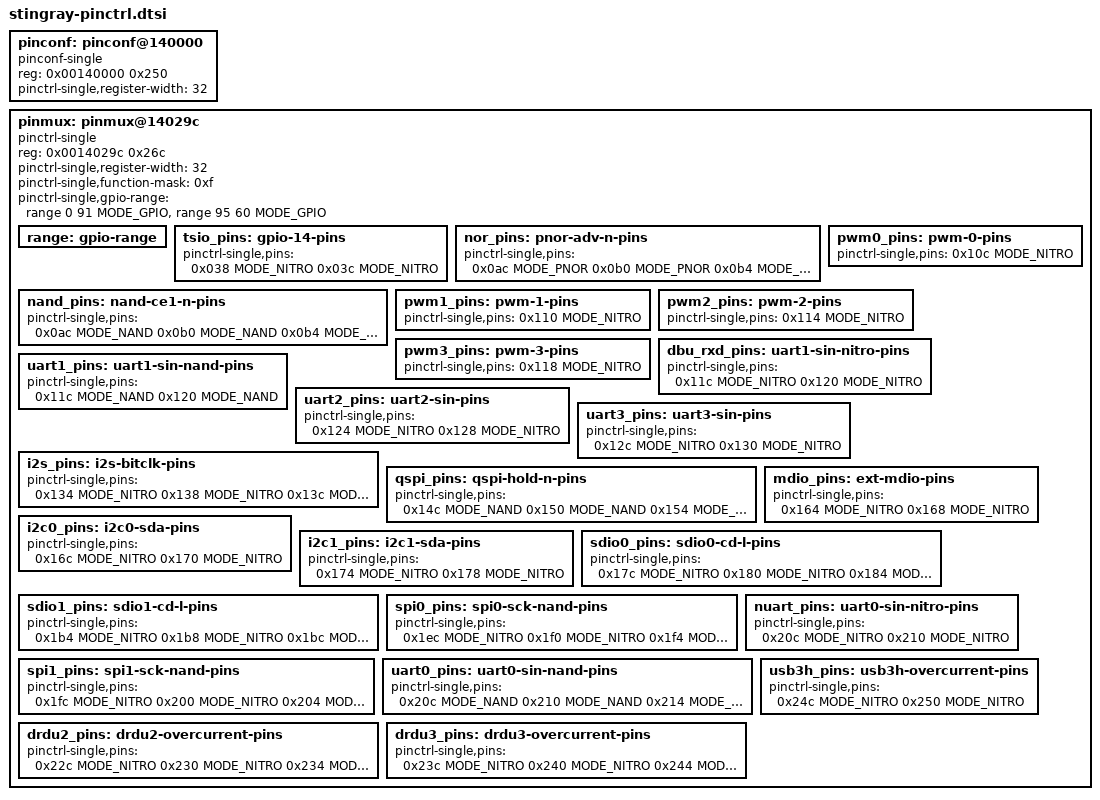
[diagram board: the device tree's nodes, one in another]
#include <dt-bindings/pinctrl/brcm,pinctrl-stingray.h>
		pinconf: pinconf@140000 {
			compatible = "pinconf-single";
			reg = <0x00140000 0x250>;
			pinctrl-single,register-width = <32>;
		};
		pinmux: pinmux@14029c {
			compatible = "pinctrl-single";
			reg = <0x0014029c 0x26c>;
			#address-cells = <1>;
			#size-cells = <0>;
			pinctrl-single,register-width = <32>;
			pinctrl-single,function-mask = <0xf>;
			pinctrl-single,gpio-range = <
				&range 0  91 MODE_GPIO
				&range 95 60 MODE_GPIO
				>;
			range: gpio-range {
				#pinctrl-single,gpio-range-cells = <3>;
			};
			tsio_pins: gpio-14-pins {
				pinctrl-single,pins = <
					0x038 MODE_NITRO  
					0x03c MODE_NITRO  
				>;
			};
			nor_pins: pnor-adv-n-pins {
				pinctrl-single,pins = <
					0x0ac MODE_PNOR  
					0x0b0 MODE_PNOR  
					0x0b4 MODE_PNOR  
					0x0b8 MODE_PNOR  
					0x0bc MODE_PNOR  
					0x0c0 MODE_PNOR  
					0x0c4 MODE_PNOR  
					0x0c8 MODE_PNOR  
					0x0cc MODE_PNOR  
					0x0d0 MODE_PNOR  
					0x0d4 MODE_PNOR  
					0x0d8 MODE_PNOR  
					0x0dc MODE_PNOR  
					0x0e0 MODE_PNOR  
					0x0e4 MODE_PNOR  
					0x0e8 MODE_PNOR  
					0x0ec MODE_PNOR  
					0x0f0 MODE_PNOR  
					0x0f4 MODE_PNOR  
					0x0f8 MODE_PNOR  
					0x0fc MODE_PNOR  
					0x100 MODE_PNOR  
					0x104 MODE_PNOR  
					0x108 MODE_PNOR  
					0x040 MODE_PNOR  
					0x044 MODE_PNOR  
					0x048 MODE_PNOR  
					0x04c MODE_PNOR  
					0x050 MODE_PNOR  
					0x054 MODE_PNOR  
					0x058 MODE_PNOR  
					0x05c MODE_PNOR  
					0x060 MODE_PNOR  
					0x064 MODE_PNOR  
					0x068 MODE_PNOR  
					0x06c MODE_PNOR  
					0x070 MODE_PNOR  
					0x074 MODE_PNOR  
					0x078 MODE_PNOR  
					0x07c MODE_PNOR  
					0x080 MODE_PNOR  
					0x084 MODE_PNOR  
					0x088 MODE_PNOR  
					0x08c MODE_PNOR  
					0x090 MODE_PNOR  
					0x094 MODE_PNOR  
					0x098 MODE_PNOR  
					0x09c MODE_PNOR  
					0x0a0 MODE_PNOR  
					0x0a4 MODE_PNOR  
					0x0a8 MODE_PNOR  
				>;
			};
			nand_pins: nand-ce1-n-pins {
				pinctrl-single,pins = <
					0x0ac MODE_NAND  
					0x0b0 MODE_NAND  
					0x0b4 MODE_NAND  
					0x0b8 MODE_NAND  
					0x0bc MODE_NAND  
					0x0c0 MODE_NAND  
					0x0c4 MODE_NAND  
					0x0c8 MODE_NAND  
					0x0cc MODE_NAND  
					0x0d0 MODE_NAND  
					0x0d4 MODE_NAND  
					0x0d8 MODE_NAND  
					0x0dc MODE_NAND  
					0x0e0 MODE_NAND  
					0x0e4 MODE_NAND  
					0x0e8 MODE_NAND  
					0x0ec MODE_NAND  
					0x0f0 MODE_NAND  
					0x0f4 MODE_NAND  
					0x0f8 MODE_NAND  
					0x0fc MODE_NAND  
					0x100 MODE_NAND  
					0x104 MODE_NAND  
					0x108 MODE_NAND  
				>;
			};
			pwm0_pins: pwm-0-pins {
				pinctrl-single,pins = <
					0x10c MODE_NITRO
				>;
			};
			pwm1_pins: pwm-1-pins {
				pinctrl-single,pins = <
					0x110 MODE_NITRO
				>;
			};
			pwm2_pins: pwm-2-pins {
				pinctrl-single,pins = <
					0x114 MODE_NITRO
				>;
			};
			pwm3_pins: pwm-3-pins {
				pinctrl-single,pins = <
					0x118 MODE_NITRO
				>;
			};
			dbu_rxd_pins: uart1-sin-nitro-pins {
				pinctrl-single,pins = <
					0x11c MODE_NITRO  
					0x120 MODE_NITRO  
				>;
			};
			uart1_pins: uart1-sin-nand-pins {
				pinctrl-single,pins = <
					0x11c MODE_NAND  
					0x120 MODE_NAND  
				>;
			};
			uart2_pins: uart2-sin-pins {
				pinctrl-single,pins = <
					0x124 MODE_NITRO  
					0x128 MODE_NITRO  
				>;
			};
			uart3_pins: uart3-sin-pins {
				pinctrl-single,pins = <
					0x12c MODE_NITRO  
					0x130 MODE_NITRO  
				>;
			};
			i2s_pins: i2s-bitclk-pins {
				pinctrl-single,pins = <
					0x134 MODE_NITRO  
					0x138 MODE_NITRO  
					0x13c MODE_NITRO  
					0x140 MODE_NITRO  
					0x144 MODE_NITRO  
					0x148 MODE_NITRO  
				>;
			};
			qspi_pins: qspi-hold-n-pins {
				pinctrl-single,pins = <
					0x14c MODE_NAND  
					0x150 MODE_NAND  
					0x154 MODE_NAND  
					0x158 MODE_NAND  
					0x15c MODE_NAND  
					0x160 MODE_NAND  
				>;
			};
			mdio_pins: ext-mdio-pins {
				pinctrl-single,pins = <
					0x164 MODE_NITRO  
					0x168 MODE_NITRO  
				>;
			};
			i2c0_pins: i2c0-sda-pins {
				pinctrl-single,pins = <
					0x16c MODE_NITRO  
					0x170 MODE_NITRO  
				>;
			};
			i2c1_pins: i2c1-sda-pins {
				pinctrl-single,pins = <
					0x174 MODE_NITRO  
					0x178 MODE_NITRO  
				>;
			};
			sdio0_pins: sdio0-cd-l-pins {
				pinctrl-single,pins = <
					0x17c MODE_NITRO  
					0x180 MODE_NITRO  
					0x184 MODE_NITRO  
					0x188 MODE_NITRO  
					0x18c MODE_NITRO  
					0x190 MODE_NITRO  
					0x194 MODE_NITRO  
					0x198 MODE_NITRO  
					0x19c MODE_NITRO  
					0x1a0 MODE_NITRO  
					0x1a4 MODE_NITRO  
					0x1a8 MODE_NITRO  
					0x1ac MODE_NITRO  
					0x1b0 MODE_NITRO  
				>;
			};
			sdio1_pins: sdio1-cd-l-pins {
				pinctrl-single,pins = <
					0x1b4 MODE_NITRO  
					0x1b8 MODE_NITRO  
					0x1bc MODE_NITRO  
					0x1c0 MODE_NITRO  
					0x1c4 MODE_NITRO  
					0x1c8 MODE_NITRO  
					0x1cc MODE_NITRO  
					0x1d0 MODE_NITRO  
					0x1d4 MODE_NITRO  
					0x1d8 MODE_NITRO  
					0x1dc MODE_NITRO  
					0x1e0 MODE_NITRO  
					0x1e4 MODE_NITRO  
					0x1e8 MODE_NITRO  
				>;
			};
			spi0_pins: spi0-sck-nand-pins {
				pinctrl-single,pins = <
					0x1ec MODE_NITRO  
					0x1f0 MODE_NITRO  
					0x1f4 MODE_NITRO  
					0x1f8 MODE_NITRO  
				>;
			};
			spi1_pins: spi1-sck-nand-pins {
				pinctrl-single,pins = <
					0x1fc MODE_NITRO  
					0x200 MODE_NITRO  
					0x204 MODE_NITRO  
					0x208 MODE_NITRO  
				>;
			};
			nuart_pins: uart0-sin-nitro-pins {
				pinctrl-single,pins = <
					0x20c MODE_NITRO  
					0x210 MODE_NITRO  
				>;
			};
			uart0_pins: uart0-sin-nand-pins {
				pinctrl-single,pins = <
					0x20c MODE_NAND  
					0x210 MODE_NAND  
					0x214 MODE_NAND  
					0x218 MODE_NAND  
					0x21c MODE_NAND  
					0x220 MODE_NAND  
					0x224 MODE_NAND  
					0x228 MODE_NAND  
				>;
			};
			drdu2_pins: drdu2-overcurrent-pins {
				pinctrl-single,pins = <
					0x22c MODE_NITRO  
					0x230 MODE_NITRO  
					0x234 MODE_NITRO  
					0x238 MODE_NITRO  
				>;
			};
			drdu3_pins: drdu3-overcurrent-pins {
				pinctrl-single,pins = <
					0x23c MODE_NITRO  
					0x240 MODE_NITRO  
					0x244 MODE_NITRO  
					0x248 MODE_NITRO  
				>;
			};
			usb3h_pins: usb3h-overcurrent-pins {
				pinctrl-single,pins = <
					0x24c MODE_NITRO  
					0x250 MODE_NITRO  
				>;
			};
		};
